# MB9AF12xL register map
File version: 1.0
Registers are 32-bit, read-write, reset 0x0 unless marked. A register's access mark holds for its fields unless they carry their own. Offsets are from the block's base; [hi:lo] are bit positions; {n}, {i} and the like mark numbered series; 'fields as' and 'values as' point back to an identical list.

## BTIOSEL03 — peripheral BTIOSEL03
Base 0x40025100
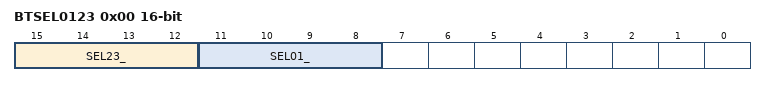
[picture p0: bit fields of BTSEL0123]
0x00 BTSEL0123 16-bit
  [15:12] SEL23_, [11:8] SEL01_

## BTIOSEL47 — peripheral BTIOSEL47
Base 0x40025300
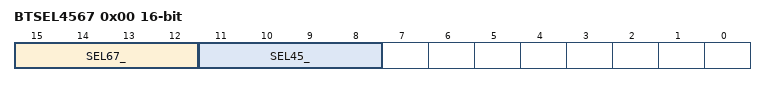
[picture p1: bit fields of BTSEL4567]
0x00 BTSEL4567 16-bit
  [15:12] SEL67_, [11:8] SEL45_

## SBSSR — peripheral SBSSR
Base 0x40025F00
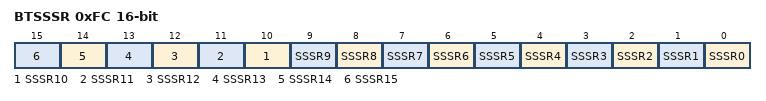
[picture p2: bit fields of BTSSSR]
0xFC BTSSSR 16-bit wo reset not defined
  [n] SSSR{n} (n=0..15)

## BT0 — peripheral BT0
Base 0x40025000
Same registers: BT1 0x40025040, BT2 0x40025080, BT3 0x400250C0, BT4 0x40025200, BT5 0x40025240, BT6 0x40025280, BT7 0x400252C0
0x00 PWM_PCSR 16-bit reset not defined (PWM view)
0x00 PPG_PRLL 16-bit reset not defined (PPG view)
0x00 RT_PCSR 16-bit reset not defined (RT view)
0x04 PWM_PDUT 16-bit reset not defined (PWM view)
0x04 PPG_PRLH 16-bit reset not defined (PPG view)
0x04 PWC_DTBF 16-bit ro (PWC view)
0x08 PWM_TMR 16-bit ro (PWM view)
0x08 PPG_TMR 16-bit ro (PPG view)
0x08 RT_TMR 16-bit ro reset not defined (RT view)
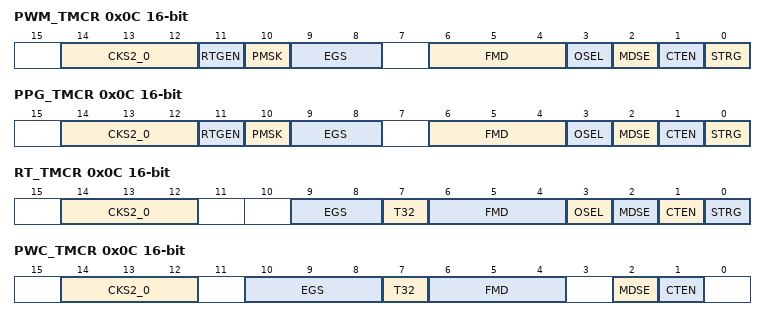
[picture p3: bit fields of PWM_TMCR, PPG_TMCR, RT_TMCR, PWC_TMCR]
0x0C PWM_TMCR 16-bit (PWM view)
  [14:12] CKS2_0, [11] RTGEN, [10] PMSK, [9:8] EGS, [6:4] FMD, [3] OSEL, [2] MDSE, [1] CTEN, [0] STRG
0x0C PPG_TMCR 16-bit (PPG view)
  fields as PWM_TMCR
0x0C RT_TMCR 16-bit (RT view)
  [14:12] CKS2_0, [9:8] EGS, [7] T32, [6:4] FMD, [3] OSEL, [2] MDSE, [1] CTEN, [0] STRG
0x0C PWC_TMCR 16-bit (PWC view)
  [14:12] CKS2_0, [10:8] EGS, [7] T32, [6:4] FMD, [2] MDSE, [1] CTEN
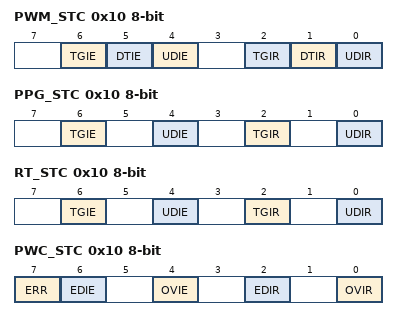
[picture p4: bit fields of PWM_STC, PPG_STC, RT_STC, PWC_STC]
0x10 PWM_STC 8-bit (PWM view)
  [6] TGIE, [5] DTIE, [4] UDIE, [2] TGIR, [1] DTIR, [0] UDIR
0x10 PPG_STC 8-bit (PPG view)
  [6] TGIE, [4] UDIE, [2] TGIR, [0] UDIR
0x10 RT_STC 8-bit (RT view)
  [6] TGIE, [4] UDIE, [2] TGIR, [0] UDIR
0x10 PWC_STC 8-bit (PWC view)
  [7] ERR ro, [6] EDIE, [4] OVIE, [2] EDIR ro, [0] OVIR
0x11 PWM_TMCR2 8-bit (PWM view)
  [0] CKS3
0x11 PPG_TMCR2 8-bit (reset mask 0x1) (PPG view)
  [1] CKS3
0x11 RT_TMCR2 8-bit (RT view)
  [0] CKS3
0x11 PWC_TMCR2 8-bit (PWC view)
  [0] CKS3

## MFT_PPG — peripheral MFT_PPG
Base 0x40024000
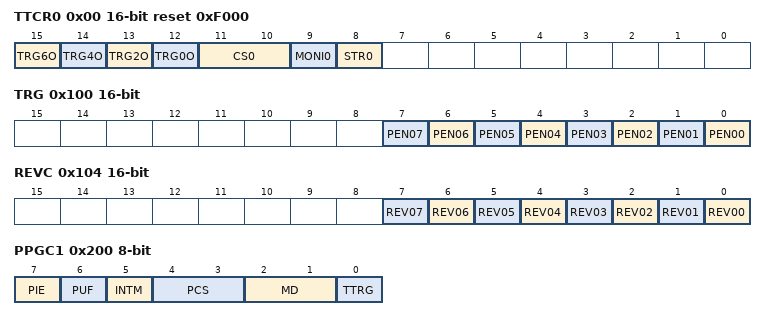
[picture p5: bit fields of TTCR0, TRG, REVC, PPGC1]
0x00 TTCR0 16-bit reset 0xF000
  [15] TRG6O, [14] TRG4O, [13] TRG2O, [12] TRG0O, [11:10] CS0, [9] MONI0 ro, [8] STR0
0x08 COMP0 16-bit (reset mask 0xFF00)
0x0C COMP2 8-bit
0x10 COMP4 16-bit (reset mask 0xFF00)
0x14 COMP6 8-bit
0x100 TRG 16-bit
  [n] PEN{n:02} (n=0..7)
0x104 REVC 16-bit
  [n] REV{n:02} (n=0..7)
0x200 PPGC1 8-bit
  [7] PIE, [6] PUF, [5] INTM, [4:3] PCS, [2:1] MD, [0] TTRG
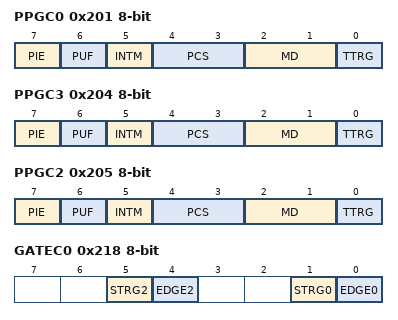
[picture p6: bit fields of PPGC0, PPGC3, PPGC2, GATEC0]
0x201 PPGC0 8-bit
  [7] PIE, [6] PUF, [5] INTM, [4:3] PCS, [2:1] MD, [0] TTRG
0x204 PPGC3 8-bit
  [7] PIE, [6] PUF, [5] INTM, [4:3] PCS, [2:1] MD, [0] TTRG
0x205 PPGC2 8-bit
  [7] PIE, [6] PUF, [5] INTM, [4:3] PCS, [2:1] MD, [0] TTRG
{0x208+4i} PRLL{i} 8-bit reset not defined (i=0..3)
  [7:0] PRLL
{0x209+4i} PRLH{i} 8-bit reset not defined (i=0..3)
  [7:0] PRLH
0x218 GATEC0 8-bit
  [5] STRG2, [4] EDGE2, [1] STRG0, [0] EDGE0
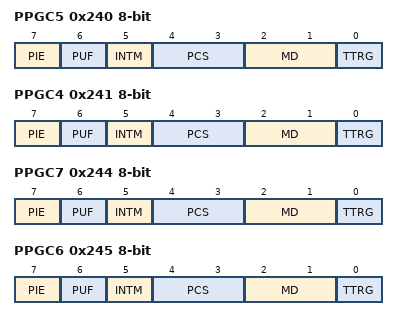
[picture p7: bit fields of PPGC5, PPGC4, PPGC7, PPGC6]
0x240 PPGC5 8-bit
  [7] PIE, [6] PUF, [5] INTM, [4:3] PCS, [2:1] MD, [0] TTRG
0x241 PPGC4 8-bit
  [7] PIE, [6] PUF, [5] INTM, [4:3] PCS, [2:1] MD, [0] TTRG
0x244 PPGC7 8-bit
  [7] PIE, [6] PUF, [5] INTM, [4:3] PCS, [2:1] MD, [0] TTRG
0x245 PPGC6 8-bit
  [7] PIE, [6] PUF, [5] INTM, [4:3] PCS, [2:1] MD, [0] TTRG
{0x238+4i} PRLL{i} 8-bit reset not defined (i=4..7)
  [7:0] PRLL
{0x239+4i} PRLH{i} 8-bit reset not defined (i=4..7)
  [7:0] PRLH
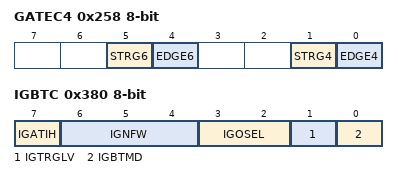
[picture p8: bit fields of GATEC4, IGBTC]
0x258 GATEC4 8-bit
  [5] STRG6, [4] EDGE6, [1] STRG4, [0] EDGE4
0x380 IGBTC 8-bit
  [7] IGATIH, [6:4] IGNFW, [3:2] IGOSEL, [1] IGTRGLV, [0] IGBTMD

## ADC0 — peripheral ADC0
Base 0x40027000
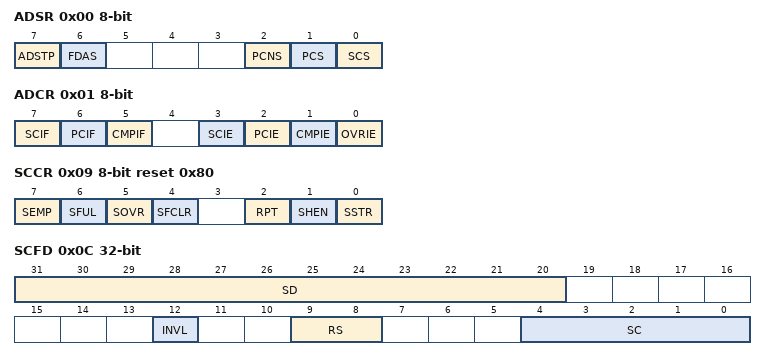
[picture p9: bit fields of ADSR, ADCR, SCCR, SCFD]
0x00 ADSR 8-bit
  [7] ADSTP, [6] FDAS, [2] PCNS, [1] PCS, [0] SCS
0x01 ADCR 8-bit
  [7] SCIF, [6] PCIF, [5] CMPIF, [3] SCIE, [2] PCIE, [1] CMPIE, [0] OVRIE
0x08 SFNS 8-bit
  [3:0] SFS
0x09 SCCR 8-bit reset 0x80
  [7] SEMP ro, [6] SFUL ro, [5] SOVR, [4] SFCLR, [2] RPT, [1] SHEN, [0] SSTR
0x0C SCFD ro
  [31:20] SD, [12] INVL, [9:8] RS, [4:0] SC
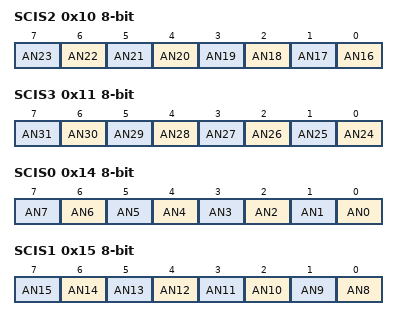
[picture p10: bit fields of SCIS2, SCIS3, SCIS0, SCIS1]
0x10 SCIS2 8-bit
  [n-16] AN{n} (n=16..23)
0x11 SCIS3 8-bit
  [n-24] AN{n} (n=24..31)
0x14 SCIS0 8-bit
  [n] AN{n} (n=0..7)
0x15 SCIS1 8-bit
  [n-8] AN{n} (n=8..15)
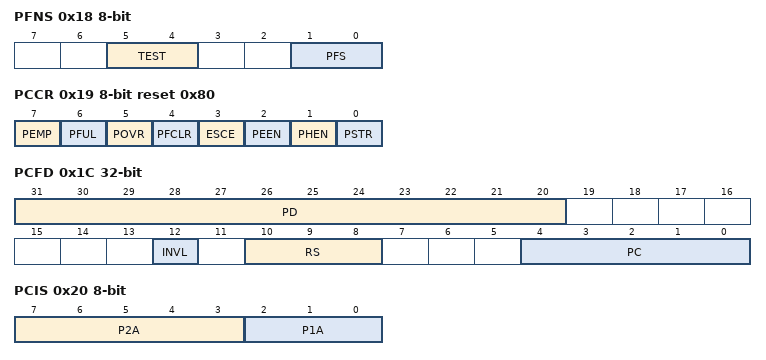
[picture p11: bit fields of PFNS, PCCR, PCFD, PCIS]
0x18 PFNS 8-bit
  [5:4] TEST ro, [1:0] PFS
0x19 PCCR 8-bit reset 0x80
  [7] PEMP ro, [6] PFUL ro, [5] POVR, [4] PFCLR, [3] ESCE, [2] PEEN, [1] PHEN, [0] PSTR
0x1C PCFD ro
  [31:20] PD, [12] INVL, [10:8] RS, [4:0] PC
0x20 PCIS 8-bit
  [7:3] P2A, [2:0] P1A
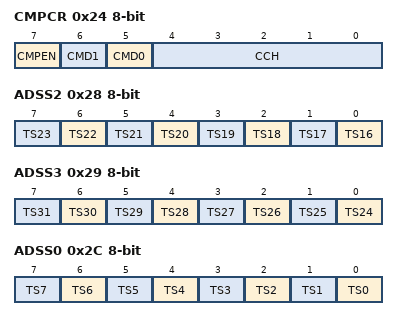
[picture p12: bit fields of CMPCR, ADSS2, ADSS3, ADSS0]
0x24 CMPCR 8-bit
  [7] CMPEN, [6] CMD1, [5] CMD0, [4:0] CCH
0x26 CMPD 16-bit
  [15:6] CMAD
0x28 ADSS2 8-bit
  [n-16] TS{n} (n=16..23)
0x29 ADSS3 8-bit
  [n-24] TS{n} (n=24..31)
0x2C ADSS0 8-bit
  [n] TS{n} (n=0..7)
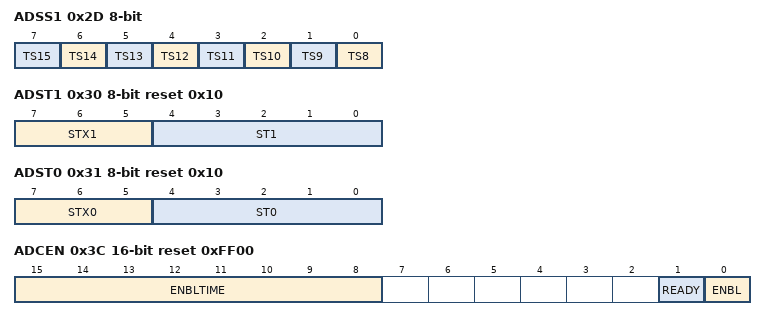
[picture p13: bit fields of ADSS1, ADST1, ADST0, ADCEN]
0x2D ADSS1 8-bit
  [n-8] TS{n} (n=8..15)
0x30 ADST1 8-bit reset 0x10
  [7:5] STX1, [4:0] ST1
0x31 ADST0 8-bit reset 0x10
  [7:5] STX0, [4:0] ST0
0x34 ADCT 8-bit reset 0x7 (reset mask 0x7)
  [7:0] CT
0x38 PRTSL 8-bit
  [3:0] PRTSL
0x39 SCTSL 8-bit
  [3:0] SCTSL
0x3C ADCEN 16-bit reset 0xFF00
  [15:8] ENBLTIME, [1] READY ro, [0] ENBL

## Notices in the file
Licence Terms
FUJITSU SEMICONDUCTOR LIMITED (gLICENSORh) hereby grants and
you (gLICENSEEh) hereby accept a non transferable, non-exclusive
licence to use and copy the deliverables (gDeliverablesh) solely for
the purpose of; (i) developing LICENSEEfs development tools and
distributing such development tools to third parties; (ii) generating
derivative representations of the Deliverables to develop and debug
software for LICENSORfs targeted devices or device series identified
within the Deliverables, (together the gPurposeh) under the following
terms and conditions:
1. Ownership.
The Deliverables are the property of LICENSOR. LICENSEE acquires no
right, title or interest in the Deliverables other than the licence
rights granted herein.
2. Use.
LICENSEE shall only be permitted to use the Deliverables for the
Purpose. LICENSEE shall not reverse engineer, decompile or
disassemble the Deliverables, in whole or in part.
3. Copies.
All copies of the Deliverables must bear the same notice(s) contained
on the original copies of the Deliverables.
4. No Warranty.
THE DELIVERABLES ARE PROVIDED gAS ISh AND ANY EXPRESS, IMPLIED OR
STATUTORY WARRANTIES, INCLUDING, BUT NOT LIMITED TO, THE IMPLIED
WARRANTIES OF MERCHANTABILITY, SATISFACTORY QUALITY AND FITNESS FOR
A PARTICULAR PURPOSE ARE DISCLAIMED.
IN NO EVENT SHALL LICENSOR BE LIABLE FOR ANY DIRECT, INDIRECT,
INCIDENTAL, SPECIAL, EXEMPLARY, OR CONSEQUENTIAL DAMAGES HOWEVER CAUSED
AND ON ANY THEORY OF LIABILITY, WHETHER IN CONTRACT, STRICT LIABILITY,
OR TORT (INCLUDING NEGLIGENCE OR OTHERWISE) ARISING IN ANY WAY OUT OF
THE USE OF THE DELIVERABLES, EVEN IF ADVISED OF THE POSSIBILITY OF SUCH
DAMAGE.
LICENSEE EXPRESSLY ASSUMES ALL LIABILITIES AND RISKS, FOR USE OR
OPERATION OF THE DELIVERABLES.
5.In the event that LICENSEE receives early access to the Deliverables,
LICENSEE acknowledges and agrees that;
(a) notwithstanding the licence grants above, LICENSEE shall only be
permitted to use the Deliverables solely internally for evaluation and
providing feedback to LICENSOR;
(b) except with respect to the limited licence grants in 5(a), LICENSEE
shall be subject to all of the terms and conditions set out above; and
(c) the Deliverables are confidential information and LICENSEE shall
maintain in confidence the Deliverables and apply security measures no
less stringent than the measures that LICENSEE applies to its own like
information, but not less than a reasonable degree of care, to prevent
unauthorised disclosure and use of the Deliverables.
